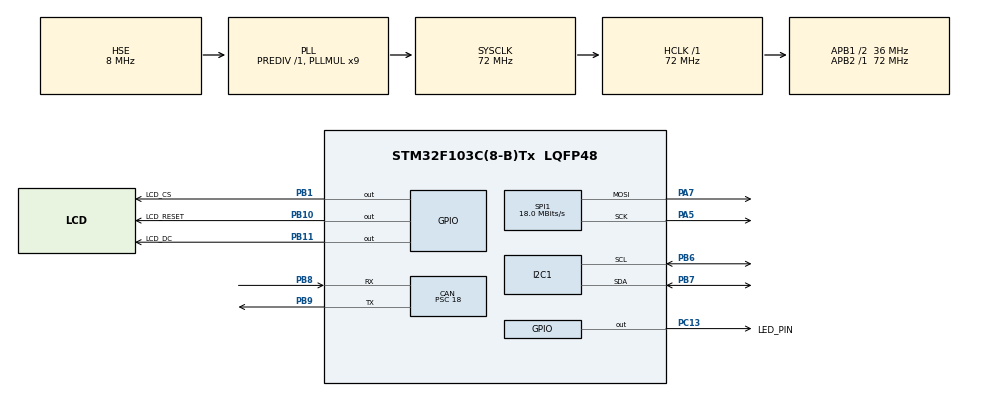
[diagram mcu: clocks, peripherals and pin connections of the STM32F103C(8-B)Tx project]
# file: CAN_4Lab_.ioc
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CAN.BS1=CAN_BS1_2TQ
CAN.CalculateBaudRate=500000
CAN.CalculateTimeBit=2000
CAN.CalculateTimeQuantum=500.0
CAN.Prescaler=18
Dma.Request0=SPI1_TX
Dma.SPI1_TX.0.Direction=DMA_MEMORY_TO_PERIPH
Dma.SPI1_TX.0.Instance=DMA1_Channel3
Dma.SPI1_TX.0.MemDataAlignment=DMA_MDATAALIGN_BYTE
Dma.SPI1_TX.0.MemInc=DMA_MINC_ENABLE
Dma.SPI1_TX.0.Mode=DMA_NORMAL
Dma.SPI1_TX.0.PeriphDataAlignment=DMA_PDATAALIGN_BYTE
Dma.SPI1_TX.0.PeriphInc=DMA_PINC_DISABLE
Dma.SPI1_TX.0.Priority=DMA_PRIORITY_LOW
Mcu.Family=STM32F1
Mcu.Name=STM32F103C(8-B)Tx
Mcu.Package=LQFP48
NVIC.CAN1_RX1_IRQn=true\:0\:0\:false\:false\:true\:true\:true\:true
NVIC.DMA1_Channel3_IRQn=true\:0\:0\:false\:false\:true\:false\:true\:true
NVIC.PriorityGroup=NVIC_PRIORITYGROUP_4
NVIC.USB_HP_CAN1_TX_IRQn=true\:0\:0\:false\:false\:true\:true\:true\:true
NVIC.USB_LP_CAN1_RX0_IRQn=true\:0\:0\:false\:false\:true\:false\:true\:true
PA13.Mode=Serial_Wire
PA13.Signal=SYS_JTMS-SWDIO
PA14.Mode=Serial_Wire
PA14.Signal=SYS_JTCK-SWCLK
PA5.Mode=TX_Only_Simplex_Unidirect_Master
PA5.Signal=SPI1_SCK
PA7.Mode=TX_Only_Simplex_Unidirect_Master
PA7.Signal=SPI1_MOSI
PB1.GPIO_Label=LCD_CS
PB1.Signal=GPIO_Output
PB10.GPIO_Label=LCD_RESET
PB10.Signal=GPIO_Output
PB11.GPIO_Label=LCD_DC
PB11.Signal=GPIO_Output
PB6.Mode=I2C
PB6.Signal=I2C1_SCL
PB7.Mode=I2C
PB7.Signal=I2C1_SDA
PB8.GPIO_PuPd=GPIO_NOPULL
PB8.Mode=CAN_Activate
PB8.Signal=CAN_RX
PB9.Mode=CAN_Activate
PB9.Signal=CAN_TX
PC13-TAMPER-RTC.GPIO_Label=LED_PIN
PC13-TAMPER-RTC.Signal=GPIO_Output
PD0-OSC_IN.Mode=HSE-External-Oscillator
PD0-OSC_IN.Signal=RCC_OSC_IN
PD1-OSC_OUT.Mode=HSE-External-Oscillator
PD1-OSC_OUT.Signal=RCC_OSC_OUT
ProjectManager.HeapSize=0x200
ProjectManager.StackSize=0x400
ProjectManager.TargetToolchain=Makefile
RCC.AHBFreq_Value=72000000
RCC.APB1CLKDivider=RCC_HCLK_DIV2
RCC.APB1Freq_Value=36000000
RCC.APB1TimFreq_Value=72000000
RCC.APB2Freq_Value=72000000
RCC.APB2TimFreq_Value=72000000
RCC.HCLKFreq_Value=72000000
RCC.PLLMUL=RCC_PLL_MUL9
RCC.PLLSourceVirtual=RCC_PLLSOURCE_HSE
RCC.SYSCLKFreq_VALUE=72000000
RCC.SYSCLKSource=RCC_SYSCLKSOURCE_PLLCLK
RCC.USBFreq_Value=48000000
RCC.USBPrescaler=RCC_USBCLKSOURCE_PLL_DIV1_5
SPI1.BaudRatePrescaler=SPI_BAUDRATEPRESCALER_4
SPI1.CalculateBaudRate=18.0 MBits/s
SPI1.Direction=SPI_DIRECTION_2LINES
SPI1.Mode=SPI_MODE_MASTER
SPI1.VirtualType=VM_MASTER
board=custom

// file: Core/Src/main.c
/* USER CODE BEGIN Header */
/**
 ******************************************************************************
 * @file           : main.c
 * @brief          : Main program body
 ******************************************************************************
 * @attention
 *
 * Copyright (c) 2025 STMicroelectronics.
 * All rights reserved.
 *
 * This software is licensed under terms that can be found in the LICENSE file
 * in the root directory of this software component.
 * If no LICENSE file comes with this software, it is provided AS-IS.
 *
 ******************************************************************************
 */
/* USER CODE END Header */
#include "main.h"
#include "can.h"
#include "dma.h"
#include "gpio.h"
#include "i2c.h"
#include "spi.h"

/* USER CODE BEGIN Includes */
#include "app_main.h"
/* USER CODE END Includes */

void SystemClock_Config(void);

int main(void) {

  /* MCU Configuration--------------------------------------------------------*/

  /* Reset of all peripherals, Initializes the Flash interface and the Systick.
   */
  HAL_Init();

  /* Configure the system clock */
  SystemClock_Config();

  /* Initialize all configured peripherals */
  MX_GPIO_Init();
  MX_DMA_Init();
  MX_CAN_Init();
  MX_SPI1_Init();
  MX_I2C1_Init();
  /* USER CODE BEGIN 2 */

  app_main();

  /* USER CODE END 2 */

  /* Infinite loop */
  while (1) {

  }
}

void SystemClock_Config(void) {
  RCC_OscInitTypeDef RCC_OscInitStruct = {0};
  RCC_ClkInitTypeDef RCC_ClkInitStruct = {0};

  /** Initializes the RCC Oscillators according to the specified parameters
   * in the RCC_OscInitTypeDef structure.
   */
  RCC_OscInitStruct.OscillatorType = RCC_OSCILLATORTYPE_HSE;
  RCC_OscInitStruct.HSEState = RCC_HSE_ON;
  RCC_OscInitStruct.HSEPredivValue = RCC_HSE_PREDIV_DIV1;
  RCC_OscInitStruct.HSIState = RCC_HSI_ON;
  RCC_OscInitStruct.PLL.PLLState = RCC_PLL_ON;
  RCC_OscInitStruct.PLL.PLLSource = RCC_PLLSOURCE_HSE;
  RCC_OscInitStruct.PLL.PLLMUL = RCC_PLL_MUL9;
  if (HAL_RCC_OscConfig(&RCC_OscInitStruct) != HAL_OK) {
    Error_Handler();
  }

  /** Initializes the CPU, AHB and APB buses clocks
   */
  RCC_ClkInitStruct.ClockType = RCC_CLOCKTYPE_HCLK | RCC_CLOCKTYPE_SYSCLK |
                                RCC_CLOCKTYPE_PCLK1 | RCC_CLOCKTYPE_PCLK2;
  RCC_ClkInitStruct.SYSCLKSource = RCC_SYSCLKSOURCE_PLLCLK;
  RCC_ClkInitStruct.AHBCLKDivider = RCC_SYSCLK_DIV1;
  RCC_ClkInitStruct.APB1CLKDivider = RCC_HCLK_DIV2;
  RCC_ClkInitStruct.APB2CLKDivider = RCC_HCLK_DIV1;

  if (HAL_RCC_ClockConfig(&RCC_ClkInitStruct, FLASH_LATENCY_2) != HAL_OK) {
    Error_Handler();
  }
}

void Error_Handler(void) {
  __disable_irq();
  while (1) {
  }
}
#ifdef USE_FULL_ASSERT
/**
 * @brief  Reports the name of the source file and the source line number
 *         where the assert_param error has occurred.
 * @param  file: pointer to the source file name
 * @param  line: assert_param error line source number
 * @retval None
 */
void assert_failed(uint8_t *file, uint32_t line) {
  /* USER CODE BEGIN 6 */
  /* User can add his own implementation to report the file name and line
     number, ex: printf("Wrong parameters value: file %s on line %d\r\n", file,
     line) */
  /* USER CODE END 6 */
}
#endif /* USE_FULL_ASSERT */
